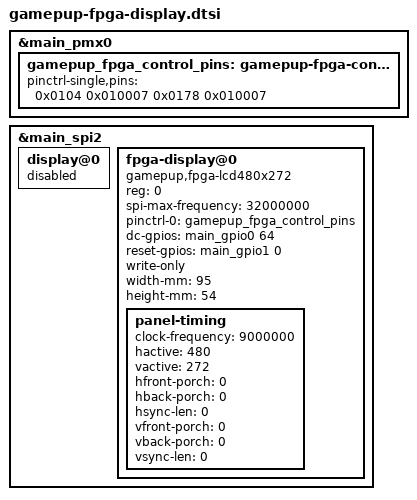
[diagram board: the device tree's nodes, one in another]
// SPDX-License-Identifier: GPL-2.0-only
/*
 * Shared body of the Tang Nano 9K FPGA display overlays (included, not compiled alone):
 * the main 480x272 panel node and the pinmux for D/C and reset.  See
 * k3-am6232-pocketbeagle2-gamepup-a4-fpga.dts for the description.
 */

&main_pmx0 {
	/* Same pads as gamepup_display_control_pins; the cape LCD node that
	 * owns that group is disabled, so this overlay claims them itself. */
	gamepup_fpga_control_pins: gamepup-fpga-control-pins {
		pinctrl-single,pins = <
			0x0104 0x010007 /* P2.17: DBI D/C, GPIO0_64 output */
			0x0178 0x010007 /* P2.19: DBI reset, GPIO1_0 output */
		>;
	};
};

&main_spi2 {
	#address-cells = <1>;
	#size-cells = <0>;

	/* Cape ILI9341 off. */
	display@0 {
		status = "disabled";
	};

	fpga-display@0 {
		compatible = "gamepup,fpga-lcd480x272", "panel-mipi-dbi-spi";
		reg = <0>;
		/* 32 MHz for jumper-wire bring-up; raise toward 48 MHz once the
		 * wiring is short and clean. */
		spi-max-frequency = <32000000>;
		pinctrl-names = "default";
		pinctrl-0 = <&gamepup_fpga_control_pins>;
		dc-gpios = <&main_gpio0 64 0>;
		reset-gpios = <&main_gpio1 0 0>;

		/* The FPGA has no MISO output: always run the init sequence. */
		write-only;

		width-mm = <95>;
		height-mm = <54>;

		/* panel-mipi-dbi accepts only size (+ optional back porch) here. */
		panel-timing {
			clock-frequency = <9000000>;
			hactive = <480>;
			vactive = <272>;
			hfront-porch = <0>;
			hback-porch = <0>;
			hsync-len = <0>;
			vfront-porch = <0>;
			vback-porch = <0>;
			vsync-len = <0>;
		};
	};
};
